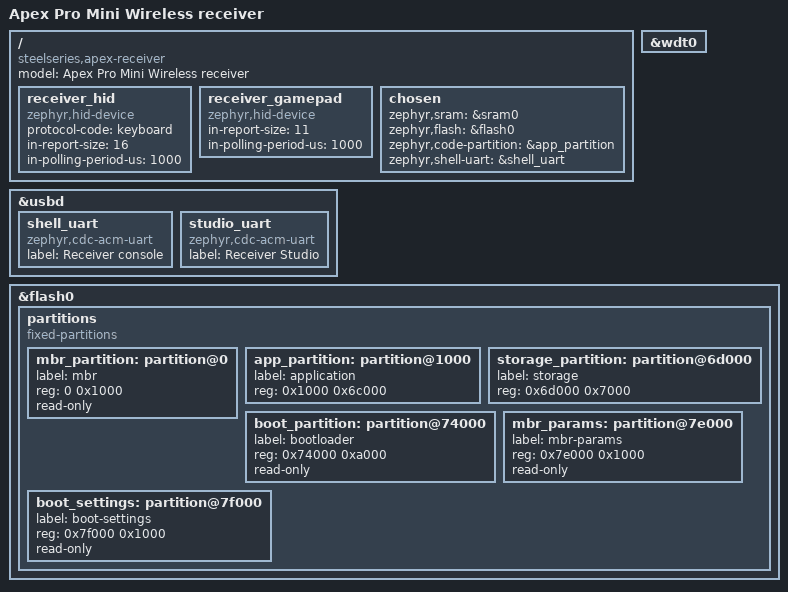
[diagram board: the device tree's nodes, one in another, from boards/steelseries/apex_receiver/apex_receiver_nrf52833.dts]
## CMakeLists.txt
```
cmake_minimum_required(VERSION 3.20.0)
list(APPEND BOARD_ROOT ${CMAKE_CURRENT_SOURCE_DIR})
find_package(Zephyr REQUIRED HINTS $ENV{ZEPHYR_BASE})
project(apex_receiver)
add_subdirectory(../radio ${CMAKE_CURRENT_BINARY_DIR}/apex_radio)
target_sources(app PRIVATE src/main.c src/usb.c src/crypto_test.c ../radio/src/apex_aes_ecb.c)
target_sources(app PRIVATE src/pair_store.c ../radio/src/apex_pair_shell.c)
if(CONFIG_APEX_RECEIVER_RADIO_PROBE)
  target_sources(app PRIVATE ../radio/src/apex_radio_probe.c)
endif()
if(CONFIG_APEX_RECEIVER_RADIO_INPUT)
  target_sources(app PRIVATE src/hid.c src/gamepad.c ../radio/src/apex_input.c ../radio/src/apex_delivery.c)
endif()
if(CONFIG_APEX_RADIO_HOPPING)
  target_sources(app PRIVATE ../radio/src/apex_hop.c ../radio/src/apex_hop_link.c)
endif()
if(CONFIG_APEX_RADIO_SHELL)
  target_sources(app PRIVATE src/keyboard_shell.c src/update.c src/studio_bridge.c ../radio/src/apex_stream.c ../radio/src/apex_shell_link.c)
endif()
target_link_options(zephyr_interface INTERFACE "-Wl,--wrap=tc_aes_encrypt")
if(DEFINED APEX_RECEIVER_BUILD_ID)
  target_compile_definitions(app PRIVATE APEX_RECEIVER_BUILD_ID="${APEX_RECEIVER_BUILD_ID}")
endif()
```

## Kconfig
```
mainmenu "Apex receiver"
source "Kconfig.zephyr"
rsource "../radio/Kconfig"
config APEX_RECEIVER_RADIO_PROBE
    bool "Fixed-channel custom radio hardware test"
    default n
    select ENTROPY_GENERATOR
config APEX_RECEIVER_RADIO_INPUT
    bool "Receive keyboard and consumer reports"
    default n
    select APEX_RECEIVER_RADIO_PROBE
    select USBD_HID_CLASS
config APEX_RECEIVER_RADIO_EVENT_RX
    bool "Wake radio processing on received packets"
    default n
    depends on APEX_RECEIVER_RADIO_PROBE
    select DYNAMIC_INTERRUPTS
```

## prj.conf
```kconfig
CONFIG_USB_DEVICE_STACK_NEXT=y
CONFIG_USBD_CDC_ACM_CLASS=y
CONFIG_SERIAL=y
CONFIG_UART_INTERRUPT_DRIVEN=y
CONFIG_UART_LINE_CTRL=y
CONFIG_CONSOLE=y
CONFIG_UART_CONSOLE=n
CONFIG_SHELL=y
CONFIG_SHELL_BACKEND_SERIAL=y
CONFIG_SHELL_BACKEND_SERIAL_RX_RING_BUFFER_SIZE=512
CONFIG_SHELL_PROMPT_UART="dongle:~$ "
CONFIG_SHELL_STACK_SIZE=2048
CONFIG_LOG=y
CONFIG_LOG_MODE_DEFERRED=y
CONFIG_LOG_DEFAULT_LEVEL=2
CONFIG_LOG_RUNTIME_FILTERING=y
CONFIG_USBD_LOG_LEVEL_WRN=y
CONFIG_UDC_DRIVER_LOG_LEVEL_WRN=y
CONFIG_USBD_CDC_ACM_LOG_LEVEL_ERR=y
CONFIG_WATCHDOG=y
CONFIG_REBOOT=y
CONFIG_HWINFO=y
CONFIG_MAIN_STACK_SIZE=2048
CONFIG_MAIN_THREAD_PRIORITY=1
CONFIG_APEX_RADIO_THREAD_PRIORITY=0
CONFIG_SYSTEM_WORKQUEUE_STACK_SIZE=2048
CONFIG_THREAD_NAME=y
CONFIG_THREAD_STACK_INFO=y
CONFIG_INIT_STACKS=y
CONFIG_ASSERT=y
CONFIG_GPIO=n
CONFIG_PINCTRL=n
CONFIG_BT=n
CONFIG_TINYCRYPT=y
CONFIG_TINYCRYPT_AES=y
CONFIG_TINYCRYPT_AES_CCM=y
CONFIG_TINYCRYPT_SHA256=y
CONFIG_TINYCRYPT_SHA256_HMAC=y
CONFIG_FLASH=y
CONFIG_FLASH_PAGE_LAYOUT=y
CONFIG_FLASH_MAP=y
CONFIG_NVS=y
CONFIG_NVS_DATA_CRC=y
CONFIG_MPU_ALLOW_FLASH_WRITE=y
```

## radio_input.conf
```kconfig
# SPDX-License-Identifier: MIT
CONFIG_APEX_RECEIVER_RADIO_INPUT=y
CONFIG_APEX_RADIO_TEST_CHANNEL=74
CONFIG_APEX_RECEIVER_RADIO_EVENT_RX=y
CONFIG_APEX_RADIO_HOPPING=y
CONFIG_APEX_RADIO_SHELL=y
```

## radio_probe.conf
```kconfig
# SPDX-License-Identifier: MIT
CONFIG_APEX_RECEIVER_RADIO_PROBE=y
```

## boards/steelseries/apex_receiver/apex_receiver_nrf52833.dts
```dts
/* SPDX-License-Identifier: MIT */
/dts-v1/;
#include <nordic/nrf52833_qiaa.dtsi>

/ {
    model = "Apex Pro Mini Wireless receiver";
    compatible = "steelseries,apex-receiver";
    receiver_hid: receiver_hid {
        compatible = "zephyr,hid-device";
        protocol-code = "keyboard";
        in-report-size = <16>;
        in-polling-period-us = <1000>;
    };
    receiver_gamepad: receiver_gamepad {
        compatible = "zephyr,hid-device";
        in-report-size = <11>;
        in-polling-period-us = <1000>;
    };
    chosen {
        zephyr,sram = &sram0;
        zephyr,flash = &flash0;
        zephyr,code-partition = &app_partition;
        zephyr,shell-uart = &shell_uart;
    };
};

zephyr_udc0: &usbd {
    status = "okay";
    shell_uart: shell_uart {
        compatible = "zephyr,cdc-acm-uart";
        label = "Receiver console";
    };
    studio_uart: studio_uart {
        compatible = "zephyr,cdc-acm-uart";
        label = "Receiver Studio";
    };
};

&wdt0 { status = "okay"; };

&flash0 {
    partitions {
        compatible = "fixed-partitions";
        #address-cells = <1>;
        #size-cells = <1>;
        mbr_partition: partition@0 { label = "mbr"; reg = <0 0x1000>; read-only; };
        app_partition: partition@1000 { label = "application"; reg = <0x1000 0x6c000>; };
        storage_partition: partition@6d000 { label = "storage"; reg = <0x6d000 0x7000>; };
        boot_partition: partition@74000 { label = "bootloader"; reg = <0x74000 0xa000>; read-only; };
        mbr_params: partition@7e000 { label = "mbr-params"; reg = <0x7e000 0x1000>; read-only; };
        boot_settings: partition@7f000 { label = "boot-settings"; reg = <0x7f000 0x1000>; read-only; };
    };
};
```

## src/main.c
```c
/* SPDX-License-Identifier: MIT */
#include <zephyr/kernel.h>
#include <zephyr/drivers/watchdog.h>
#include <zephyr/shell/shell.h>
#include <zephyr/sys/reboot.h>
#include <hal/nrf_power.h>
#include "apex_pair.h"
#include "apex_aes.h"
#if IS_ENABLED(CONFIG_APEX_RECEIVER_RADIO_PROBE)
#include "apex_radio_probe.h"
#endif

int receiver_usb_init(void);
#if IS_ENABLED(CONFIG_APEX_RADIO_SHELL)
int receiver_keyboard_command(const struct shell *sh, size_t argc, char **argv);
int receiver_update_start(const struct shell *sh, size_t argc, char **argv);
#endif
#if IS_ENABLED(CONFIG_APEX_RECEIVER_RADIO_INPUT)
#include "apex_radio_input.h"
int receiver_hid_init(void);
int receiver_hid_benchmark(const struct shell *sh, size_t argc, char **argv);
void receiver_hid_poll(void);
void receiver_hid_wait(void);
int receiver_hid_status(const struct shell *sh, size_t argc, char **argv);
int receiver_hid_test_hold(const struct shell *sh, size_t argc, char **argv);
#endif
int receiver_pair_storage_init(const struct shell *sh, size_t argc, char **argv);
int receiver_crypto_test(const struct shell *sh, size_t argc, char **argv);
#ifndef APEX_RECEIVER_BUILD_ID
#define APEX_RECEIVER_BUILD_ID "unrecorded-local-build"
#endif
static uint32_t reset_reason;
static const struct device *const watchdog = DEVICE_DT_GET(DT_NODELABEL(wdt0));
static int watchdog_channel;
static bool inherited_watchdog;

static void enter_bootloader(void)
{
    NRF_POWER->GPREGRET = 0x57;
    sys_reboot(SYS_REBOOT_COLD);
}

void k_sys_fatal_error_handler(unsigned int reason, const struct arch_esf *esf)
{
    ARG_UNUSED(reason);
    ARG_UNUSED(esf);
    enter_bootloader();
    CODE_UNREACHABLE;
}

static int cmd_status(const struct shell *sh, size_t argc, char **argv)
{
    ARG_UNUSED(argc); ARG_UNUSED(argv);
    shell_print(sh, "Apex receiver: radio=%s, HID forwarding=%s",
                IS_ENABLED(CONFIG_APEX_RECEIVER_RADIO_PROBE) ? "enabled" : "disabled",
                IS_ENABLED(CONFIG_APEX_RECEIVER_RADIO_INPUT) ? "enabled" : "disabled");
    shell_print(sh, "build: %s", APEX_RECEIVER_BUILD_ID);
    shell_print(sh, "uptime: %lld ms, reset reason: 0x%08x", k_uptime_get(), reset_reason);
    shell_print(sh, "watchdog: %u ticks, %s", NRF_WDT->CRV,
                inherited_watchdog ? "inherited across reset" : "started by receiver");
    shell_print(sh, "application: 0x1000..0x6d000, pairing storage: 0x6d000..0x74000");
    return 0;
}

static void reboot_work(struct k_work *work)
{
    ARG_UNUSED(work);
    enter_bootloader();
}
static K_WORK_DELAYABLE_DEFINE(dfu_work, reboot_work);

static int cmd_dfu(const struct shell *sh, size_t argc, char **argv)
{
    ARG_UNUSED(argc); ARG_UNUSED(argv);
    shell_print(sh, "Rebooting the dongle into APEXDONGLE.");
    k_work_reschedule(&dfu_work, K_MSEC(200));
    return 0;
}

#if IS_ENABLED(CONFIG_APEX_RECEIVER_RADIO_INPUT)
static int cmd_reconnect(const struct shell *sh, size_t argc, char **argv)
{
    ARG_UNUSED(argc); ARG_UNUSED(argv);
    apex_radio_request_session();
    shell_print(sh, "Radio session restarting.");
    return 0;
}
#endif

SHELL_STATIC_SUBCMD_SET_CREATE(dongle_commands,
#if IS_ENABLED(CONFIG_APEX_RADIO_SHELL)
    SHELL_CMD_ARG(upload, NULL, "Binary keyboard update transfer; used by tools/dongle.py.", receiver_update_start, 1, 0),
#endif
#if IS_ENABLED(CONFIG_APEX_RECEIVER_RADIO_PROBE)
    SHELL_CMD_ARG(radio_test, NULL, "Radio connection and delivery counters.", apex_radio_probe_status, 1, 0),
#endif
#if IS_ENABLED(CONFIG_APEX_RECEIVER_RADIO_INPUT)
    SHELL_CMD_ARG(reconnect, NULL, "Start a fresh radio session without changing pairing.", cmd_reconnect, 1, 0),
    SHELL_CMD_ARG(hid_status, NULL, "USB HID state and media report counters.", receiver_hid_status, 1, 0),
    SHELL_CMD_ARG(hid_bench, NULL, "Pause radio and send 1000 empty USB reports.", receiver_hid_benchmark, 1, 0),
    SHELL_CMD_ARG(hid_test_hold, NULL, "Delay HID for 500 ms and restart the radio session.", receiver_hid_test_hold, 1, 0),
#endif
    SHELL_CMD_ARG(pair_storage_init, NULL, "Initialize unreadable pairing pages; requires confirm.", receiver_pair_storage_init, 1, 1),
    SHELL_CMD_ARG(pair, NULL, "USB pairing: status, write [replace], clear confirm.", apex_pair_shell, 1, 2),
    SHELL_CMD_ARG(status, NULL, "Receiver firmware and reset status.", cmd_status, 1, 0),
    SHELL_CMD_ARG(dfu, NULL, "Enter the dongle USB bootloader.", cmd_dfu, 1, 0),
    SHELL_CMD_ARG(crypto_test, NULL, "Run packet crypto checks locally; no radio traffic.", receiver_crypto_test, 1, 0),
    SHELL_SUBCMD_SET_END);
SHELL_CMD_REGISTER(dongle, &dongle_commands, "Apex receiver commands.", NULL);
#if IS_ENABLED(CONFIG_APEX_RADIO_SHELL)
SHELL_CMD_ARG_REGISTER(keyboard, NULL, "Keyboard commands over radio.", receiver_keyboard_command, 1, 16);
#endif

int main(void)
{
    /* Receiver builds have no Bluetooth controller or other ECB owner. */
    apex_aes_enable();
    reset_reason = NRF_POWER->RESETREAS;
    NRF_POWER->RESETREAS = reset_reason;
    struct wdt_timeout_cfg cfg = {
        .window = {.min = 0, .max = 5000},
        .flags = WDT_FLAG_RESET_SOC,
    };
    /* nRF52 watchdog configuration survives software resets and cannot be
     * changed while running. Adopt it after an update instead of rebooting. */
    inherited_watchdog = NRF_WDT->RUNSTATUS != 0;
    if (!inherited_watchdog) {
        if (!device_is_ready(watchdog)) enter_bootloader();
        watchdog_channel = wdt_install_timeout(watchdog, &cfg);
        if (watchdog_channel < 0 || wdt_setup(watchdog, WDT_OPT_PAUSE_HALTED_BY_DBG)) {
            enter_bootloader();
        }
    }
#if IS_ENABLED(CONFIG_APEX_RECEIVER_RADIO_INPUT)
    if (receiver_hid_init()) enter_bootloader();
#endif
    if (receiver_usb_init()) enter_bootloader();
#if IS_ENABLED(CONFIG_APEX_RECEIVER_RADIO_PROBE)
    apex_radio_probe_start(APEX_RECEIVER);
#endif
    for (;;) {
        if (inherited_watchdog) {
            for (unsigned int i = 0; i < 8; ++i) {
                if (NRF_WDT->RREN & BIT(i)) NRF_WDT->RR[i] = 0x6e524635;
            }
        } else {
            wdt_feed(watchdog, watchdog_channel);
        }
#if IS_ENABLED(CONFIG_APEX_RECEIVER_RADIO_INPUT)
        receiver_hid_poll();
        receiver_hid_wait();
#else
        k_sleep(K_MSEC(100));
#endif
    }
    return 0;
}
```

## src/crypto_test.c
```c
/* SPDX-License-Identifier: MIT */
#include <string.h>
#include <zephyr/kernel.h>
#include <zephyr/shell/shell.h>
#include "apex_packet.h"

/* This local test never accesses pairing storage or the radio. */
int receiver_crypto_test(const struct shell *sh, size_t argc, char **argv)
{
    ARG_UNUSED(argc); ARG_UNUSED(argv);
    static const uint8_t reference[] = {
        0x01, 0x01, 0x00, 0x10, 0x01, 0x00, 0x00, 0x00,
        0xaf, 0x5f, 0xe1, 0xd4, 0x67, 0x03, 0x47, 0xd6,
        0x9c, 0x91, 0x80, 0xba, 0x07, 0xc6, 0x39, 0x55,
        0xe7, 0xb8, 0xd0, 0xf0, 0x68, 0x32, 0x01, 0xb2,
        0xcb, 0x6f, 0x08, 0x20, 0x8f, 0x7b, 0xb3, 0x3c,
    };
    struct apex_session tx, rx;
    uint8_t key[16], kn[16], dn[16], packet[APEX_PACKET_MAX], output[64], type;
    for (unsigned int i = 0; i < 16; ++i) {
        key[i] = i;
        kn[i] = i + 16;
        dn[i] = i + 32;
    }
    int rc = apex_session_init(&tx, key, kn, dn, APEX_KEYBOARD);
    if (!rc) rc = apex_session_init(&rx, key, kn, dn, APEX_RECEIVER);
    uint32_t start = k_cycle_get_32();
    for (unsigned int i = 0; !rc && i < 100; ++i) {
        int n = apex_packet_encode(&tx, APEX_PACKET_INPUT, kn, sizeof(kn), packet, sizeof(packet));
        if (i == 0 && (n != sizeof(reference) || memcmp(packet, reference, sizeof(reference)))) {
            rc = -EIO;
            break;
        }
        if (n < 0 || apex_packet_decode(&rx, packet, n, &type, output, sizeof(output)) != 16 ||
            type != APEX_PACKET_INPUT || memcmp(output, kn, 16)) {
            rc = -EIO;
            break;
        }
        if (apex_packet_decode(&rx, packet, n, &type, output, sizeof(output)) != APEX_PACKET_REPLAY) {
            rc = -EIO;
        }
    }
    uint32_t elapsed = k_cycle_get_32() - start;
    apex_session_clear(&tx);
    apex_session_clear(&rx);
    if (rc) {
        shell_error(sh, "Packet crypto test failed: %d", rc);
    } else {
        shell_print(sh, "100 encrypt/decrypt/replay checks passed; %llu us total",
                    k_cyc_to_us_floor64(elapsed));
    }
    return rc;
}
```

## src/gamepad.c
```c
/* SPDX-License-Identifier: MIT */
#include "gamepad.h"
#include "apex_radio_input.h"
#include <zephyr/kernel.h>
#include <zephyr/usb/class/usbd_hid.h>
#include <zephyr/drivers/usb/udc_buf.h>
#include <zephyr/shell/shell.h>

static const struct device *const hid = DEVICE_DT_GET(DT_NODELABEL(receiver_gamepad));
static const uint8_t descriptor[] = { APEX_GAMEPAD_DESCRIPTOR };
static struct k_spinlock lock;
static uint8_t current[APEX_GAMEPAD_REPORT_SIZE];
static bool ready, busy, dirty, enabled;
static bool live;
static uint32_t received_at;
static uint32_t reports, errors;
UDC_STATIC_BUF_DEFINE(tx, APEX_GAMEPAD_REPORT_SIZE);

void apex_radio_gamepad_receive(bool on, const uint8_t *report)
{
    k_spinlock_key_t key = k_spin_lock(&lock);
    enabled = on;
    live = on;
    received_at = k_uptime_get_32();
    if (on) memcpy(current, report, sizeof(current));
    else apex_gamepad_neutral(current);
    dirty = true;
    k_spin_unlock(&lock, key);
    receiver_usb_gamepad(on);
}

void receiver_gamepad_release(void)
{
    k_spinlock_key_t key = k_spin_lock(&lock);
    live = false;
    apex_gamepad_neutral(current);
    dirty = true;
    k_spin_unlock(&lock, key);
}

static void iface_ready(const struct device *dev, bool on)
{
    ARG_UNUSED(dev);
    k_spinlock_key_t key = k_spin_lock(&lock);
    ready = on;
    dirty = true;
    k_spin_unlock(&lock, key);
}

static void report_done(const struct device *dev, const uint8_t *const report, int status)
{
    ARG_UNUSED(dev); ARG_UNUSED(report);
    k_spinlock_key_t key = k_spin_lock(&lock);
    busy = false;
    if (status) { errors++; dirty = true; }
    else reports++;
    k_spin_unlock(&lock, key);
}

static int get_report(const struct device *dev, uint8_t type, uint8_t id,
                      uint16_t length, uint8_t *const report)
{
    ARG_UNUSED(dev);
    if (type != HID_REPORT_TYPE_INPUT || id || length < sizeof(current)) return -ENOTSUP;
    k_spinlock_key_t key = k_spin_lock(&lock);
    memcpy(report, current, sizeof(current));
    k_spin_unlock(&lock, key);
    return sizeof(current);
}

static const struct hid_device_ops ops = {
    .iface_ready = iface_ready,
    .get_report = get_report,
    .input_report_complete = report_done,
};

void receiver_gamepad_poll(void)
{
    k_spinlock_key_t key = k_spin_lock(&lock);
    if (live && k_uptime_get_32() - received_at >= 100) {
        apex_gamepad_neutral(current);
        dirty = true;
        live = false;
    }
    if (!ready || busy || !dirty) { k_spin_unlock(&lock, key); return; }
    memcpy(tx, current, sizeof(current));
    busy = true;
    dirty = false;
    k_spin_unlock(&lock, key);
    int rc = hid_device_submit_report(hid, sizeof(current), tx);
    if (rc) {
        key = k_spin_lock(&lock);
        busy = false;
        dirty = true;
        errors++;
        k_spin_unlock(&lock, key);
    }
}

int receiver_gamepad_init(void)
{
    apex_gamepad_neutral(current);
    return hid_device_register(hid, descriptor, sizeof(descriptor), &ops);
}

void receiver_gamepad_status(const struct shell *sh)
{
    k_spinlock_key_t key = k_spin_lock(&lock);
    bool e = enabled, r = ready, b = busy;
    uint32_t n = reports, err = errors;
    k_spin_unlock(&lock, key);
    shell_print(sh, "GAMEPAD enabled=%u ready=%u busy=%u reports=%u errors=%u", e, r, b, n, err);
}
```

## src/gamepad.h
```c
/* SPDX-License-Identifier: MIT */
#ifndef RECEIVER_GAMEPAD_H
#define RECEIVER_GAMEPAD_H
#include <stdbool.h>
struct shell;
int receiver_gamepad_init(void);
void receiver_gamepad_poll(void);
void receiver_gamepad_release(void);
void receiver_gamepad_status(const struct shell *sh);
void receiver_usb_gamepad(bool enabled);
#endif
```

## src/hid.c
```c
/* SPDX-License-Identifier: MIT */
#include "apex_radio_input.h"
#include "apex_latency.h"
#include "gamepad.h"
#include <string.h>
#include <zephyr/kernel.h>
#include <zephyr/usb/class/usbd_hid.h>
#include <zephyr/drivers/usb/udc_buf.h>
#include <zephyr/sys/atomic.h>
#include <zephyr/shell/shell.h>
#include <zephyr/sys/byteorder.h>

/* Report bodies match v0.1.4: six keyboard usages and six 16-bit consumer usages. */
static const uint8_t descriptor[] = {
    0x05,0x01, 0x09,0x06, 0xa1,0x01, 0x85,0x01,
    0x05,0x07, 0x19,0xe0, 0x29,0xe7, 0x15,0x00, 0x25,0x01,
    0x75,0x01, 0x95,0x08, 0x81,0x02,
    0x75,0x08, 0x95,0x01, 0x81,0x03,
    0x05,0x08, 0x19,0x01, 0x29,0x05, 0x75,0x01, 0x95,0x05, 0x91,0x02,
    0x75,0x03, 0x95,0x01, 0x91,0x03,
    0x05,0x07, 0x19,0x00, 0x29,0xff, 0x15,0x00, 0x26,0xff,0x00,
    0x75,0x08, 0x95,0x06, 0x81,0x00, 0xc0,
    0x05,0x0c, 0x09,0x01, 0xa1,0x01, 0x85,0x02,
    0x15,0x00, 0x26,0xff,0x0f, 0x19,0x00, 0x2a,0xff,0x0f,
    0x75,0x10, 0x95,0x06, 0x81,0x00, 0xc0,
};
static const struct device *const hid = DEVICE_DT_GET(DT_NODELABEL(receiver_hid));
UDC_STATIC_BUF_DEFINE(report, 16);
static struct k_spinlock lock;
static bool ready, busy;
static uint8_t release_mask = 3, protocol = HID_PROTOCOL_REPORT;
static uint32_t generation, pending_generation, pending_sequence, delivered_sequence;
static uint8_t pending_type;
static uint8_t keyboard[8], consumer[12];
static atomic_t leds;
static int64_t hold_until;
static uint32_t completed[2], releases, submit_errors, transfer_errors;
static uint16_t last_media_usage;
static uint32_t submitted_at, delivered_at, usb_max_us;
static struct apex_latency usb_latency;
static struct apex_latency usb_interval;
static uint32_t last_usb_at, last_usb_generation;
static bool have_usb_completion;
static struct apex_delivery_rx delivery;
static K_SEM_DEFINE(hid_event, 0, 1);

void receiver_hid_wait(void)
{
    /* Retry temporary submission failures even if USB produces no callback. */
    k_sem_take(&hid_event, K_MSEC(1));
}

void apex_radio_delivery_status(struct apex_delivery_ack *ack)
{
    k_spinlock_key_t key = k_spin_lock(&lock);
    apex_delivery_status(&delivery, atomic_get(&leds), ack);
    k_spin_unlock(&lock, key);
}

uint32_t apex_radio_completed(uint32_t *completed_at)
{
    k_spinlock_key_t key = k_spin_lock(&lock);
    uint32_t sequence = release_mask ? 0 : delivered_sequence;
    *completed_at = delivered_at;
    k_spin_unlock(&lock, key);
    return sequence;
}

void apex_radio_release(void)
{
    k_spinlock_key_t key = k_spin_lock(&lock);
    generation++;
    releases++;
    delivered_sequence = 0;
    apex_delivery_rx_reset(&delivery);
    release_mask = 3;
    memset(keyboard, 0, sizeof(keyboard));
    memset(consumer, 0, sizeof(consumer));
    k_spin_unlock(&lock, key);
    receiver_gamepad_release();
    k_sem_give(&hid_event);
}

static void iface_ready(const struct device *dev, bool is_ready)
{
    ARG_UNUSED(dev);
    k_spinlock_key_t key = k_spin_lock(&lock);
    ready = is_ready;
    k_spin_unlock(&lock, key);
    apex_radio_release();
    apex_radio_request_session();
}

static void report_done(const struct device *dev, const uint8_t *data, int status)
{
    ARG_UNUSED(dev); ARG_UNUSED(data);
    bool notify = false;
    k_spinlock_key_t key = k_spin_lock(&lock);
    if (status) transfer_errors++;
    if (!status && busy && pending_generation == generation) {
        delivered_sequence = pending_sequence;
        if (pending_sequence) {
            apex_delivery_complete(&delivery, pending_sequence);
            delivered_at = k_cycle_get_32();
            if (have_usb_completion && last_usb_generation == pending_generation)
                apex_latency_add(&usb_interval, k_cyc_to_us_floor32(delivered_at - last_usb_at));
            last_usb_at = delivered_at;
            last_usb_generation = pending_generation;
            have_usb_completion = true;
            uint32_t elapsed = k_cyc_to_us_floor32(delivered_at - submitted_at);
            apex_latency_add(&usb_latency, elapsed);
            if (elapsed > usb_max_us) usb_max_us = elapsed;
            notify = true;
            completed[pending_type - 1]++;
            if (pending_type == APEX_INPUT_CONSUMER && sys_get_le16(consumer)) {
                last_media_usage = sys_get_le16(consumer);
            }
        }
        if (!pending_sequence) release_mask &= ~(1u << (pending_type - 1));
    }
    busy = false;
    k_spin_unlock(&lock, key);
    k_sem_give(&hid_event);
    if (notify) apex_radio_delivery_notify();
}

static void set_protocol(const struct device *dev, uint8_t value)
{
    ARG_UNUSED(dev);
    k_spinlock_key_t key = k_spin_lock(&lock);
    protocol = value;
    k_spin_unlock(&lock, key);
    apex_radio_release();
    apex_radio_request_session();
}

static int get_report(const struct device *dev, uint8_t type, uint8_t id,
                      uint16_t length, uint8_t *buf)
{
    ARG_UNUSED(dev);
    k_spinlock_key_t key = k_spin_lock(&lock);
    bool boot = protocol == HID_PROTOCOL_BOOT;
    if (boot && id == 0) id = APEX_INPUT_KEYBOARD;
    if (type != HID_REPORT_TYPE_INPUT || !apex_input_size(id)) {
        k_spin_unlock(&lock, key);
        return -ENOTSUP;
    }
    size_t n = apex_input_size(id), prefix = boot ? 0 : 1;
    if (length < n + prefix || (boot && id != APEX_INPUT_KEYBOARD)) {
        k_spin_unlock(&lock, key);
        return -EINVAL;
    }
    if (prefix) buf[0] = id;
    memcpy(buf + prefix, id == APEX_INPUT_KEYBOARD ? keyboard : consumer, n);
    k_spin_unlock(&lock, key);
    return n + prefix;
}

static int set_report(const struct device *dev, uint8_t type, uint8_t id,
                      uint16_t length, const uint8_t *buf)
{
    ARG_UNUSED(dev);
    if (type != HID_REPORT_TYPE_OUTPUT || (id != 1 && id != 0) || length != 1) return -EINVAL;
    atomic_set(&leds, buf[0] & 0x1f);
    return 0;
}

static const struct hid_device_ops ops = {
    .iface_ready = iface_ready, .input_report_complete = report_done,
    .get_report = get_report, .set_report = set_report, .set_protocol = set_protocol,
};

static int submit(uint32_t sequence, uint8_t type, const uint8_t *data, uint32_t expected_generation)
{
    k_spinlock_key_t key = k_spin_lock(&lock);
    if (expected_generation != generation) {
        k_spin_unlock(&lock, key);
        return -ECANCELED;
    }
    if (k_uptime_get() < hold_until) {
        k_spin_unlock(&lock, key);
        return -EAGAIN;
    }
    if (sequence && sequence == delivered_sequence && !release_mask) {
        k_spin_unlock(&lock, key);
        return 0;
    }
    if (!ready || busy || (sequence && release_mask)) {
        k_spin_unlock(&lock, key);
        return -EAGAIN;
    }
    if (protocol == HID_PROTOCOL_BOOT && type == APEX_INPUT_CONSUMER) {
        if (!sequence) release_mask &= ~2u;
        else {
            delivered_sequence = sequence;
            delivered_at = k_cycle_get_32();
            apex_delivery_complete(&delivery, sequence);
        }
        k_spin_unlock(&lock, key);
        k_sem_give(&hid_event);
        apex_radio_delivery_notify();
        return 0;
    }
    size_t n = apex_input_size(type), prefix = protocol == HID_PROTOCOL_BOOT ? 0 : 1;
    if (prefix) report[0] = type;
    memcpy(report + prefix, data, n);
    memcpy(type == APEX_INPUT_KEYBOARD ? keyboard : consumer, data, n);
    pending_sequence = sequence;
    pending_type = type;
    pending_generation = generation;
    submitted_at = k_cycle_get_32();
    busy = true;
    k_spin_unlock(&lock, key);
    int rc = hid_device_submit_report(hid, n + prefix, report);
    if (rc) {
        key = k_spin_lock(&lock);
        submit_errors++;
        busy = false;
        k_spin_unlock(&lock, key);
    }
    return rc ? rc : -EAGAIN;
}

int apex_radio_deliver(const struct apex_input_frame *frame)
{
    k_spinlock_key_t key = k_spin_lock(&lock);
    int rc = apex_delivery_receive(&delivery, frame);
    k_spin_unlock(&lock, key);
    if (!rc) k_sem_give(&hid_event);
    return rc == -2 ? -EAGAIN : rc < 0 ? -EINVAL : 0;
}

void receiver_hid_poll(void)
{
    static const uint8_t zero[12];
    k_spinlock_key_t key = k_spin_lock(&lock);
    uint8_t type = release_mask & 1 ? APEX_INPUT_KEYBOARD :
                   release_mask & 2 ? APEX_INPUT_CONSUMER : 0;
    uint32_t current_generation = generation;
    struct apex_input_frame frame;
    bool queued = !type && apex_delivery_front(&delivery, &frame);
    k_spin_unlock(&lock, key);
    if (type) (void)submit(0, type, zero, current_generation);
    else if (queued) (void)submit(frame.sequence, frame.type, frame.data, current_generation);
    receiver_gamepad_poll();
}

int receiver_hid_init(void)
{
    int rc = hid_device_register(hid, descriptor, sizeof(descriptor), &ops);
    return rc ? rc : receiver_gamepad_init();
}

int receiver_hid_benchmark(const struct shell *sh, size_t argc, char **argv)
{
    ARG_UNUSED(argc); ARG_UNUSED(argv);
    if (!apex_radio_pause()) return -EBUSY;
    apex_radio_release();
    int rc = 0;
    int64_t deadline = k_uptime_get() + 1000;
    for (;;) {
        k_spinlock_key_t key = k_spin_lock(&lock);
        bool available = ready && !busy && !release_mask;
        k_spin_unlock(&lock, key);
        if (available) break;
        if (k_uptime_get() >= deadline) { rc = -ETIMEDOUT; goto done; }
        k_sleep(K_MSEC(1));
    }
    uint32_t sent = 0, complete = 0, started = k_cycle_get_32();
    deadline = k_uptime_get() + 5000;
    while (complete < 1000 && k_uptime_get() < deadline) {
        while (sent < 1000) {
            struct apex_input_frame frame = {.sequence = sent + 1, .type = APEX_INPUT_KEYBOARD};
            int result = apex_radio_deliver(&frame);
            if (result == -EAGAIN) break;
            if (result) { rc = result; goto report; }
            sent++;
        }
        uint32_t completed_at;
        complete = apex_radio_completed(&completed_at);
        if (complete < 1000) k_sleep(K_MSEC(1));
    }
    if (complete < 1000) rc = -ETIMEDOUT;
report:;
    uint32_t elapsed = k_cyc_to_us_floor32(k_cycle_get_32() - started);
    shell_print(sh, "USB_BENCH sent=%u completed=%u elapsed_us=%u reports_per_s=%llu error=%d",
                sent, complete, elapsed, elapsed ? (unsigned long long)complete * 1000000 / elapsed : 0, rc);
done:
    apex_radio_release();
    apex_radio_resume();
    return rc;
}

int receiver_hid_status(const struct shell *sh, size_t argc, char **argv)
{
    receiver_gamepad_status(sh);
    ARG_UNUSED(argc); ARG_UNUSED(argv);
    k_spinlock_key_t key = k_spin_lock(&lock);
    bool r = ready, b = busy;
    uint8_t p = protocol, mask = release_mask;
    uint32_t keys = completed[0], media = completed[1], cleared = releases, errors = submit_errors;
    uint32_t failed = transfer_errors;
    uint32_t usb_us = usb_max_us;
    struct apex_latency latency = usb_latency;
    struct apex_latency interval = usb_interval;
    uint16_t usage = last_media_usage;
    k_spin_unlock(&lock, key);
    shell_print(sh, "HID ready=%u busy=%u protocol=%u release_pending=%u leds=%02lx",
                r, b, p, mask, (unsigned long)atomic_get(&leds));
    shell_print(sh, "HID keyboard=%lu consumer=%lu releases=%lu submit_errors=%lu last_media=%04x",
                (unsigned long)keys, (unsigned long)media, (unsigned long)cleared,
                (unsigned long)errors, usage);
    shell_print(sh, "HID transfer_errors=%lu", (unsigned long)failed);
    shell_print(sh, "HID submit_to_complete_max_us=%lu", (unsigned long)usb_us);
    shell_print(sh, "USB_COMPLETE count=%u min_us=%u max_us=%u total_us=%llu",
                latency.count, latency.min_us, latency.max_us,
                (unsigned long long)latency.total_us);
    shell_print(sh, "USB_COMPLETE buckets=%u,%u,%u,%u,%u,%u",
                latency.buckets[0], latency.buckets[1], latency.buckets[2],
                latency.buckets[3], latency.buckets[4], latency.buckets[5]);
    shell_print(sh, "USB_INTERVAL count=%u min_us=%u max_us=%u total_us=%llu",
                interval.count, interval.min_us, interval.max_us,
                (unsigned long long)interval.total_us);
    shell_print(sh, "USB_INTERVAL buckets=%u,%u,%u,%u,%u,%u",
                interval.buckets[0], interval.buckets[1], interval.buckets[2],
                interval.buckets[3], interval.buckets[4], interval.buckets[5]);
    return 0;
}

int receiver_hid_test_hold(const struct shell *sh, size_t argc, char **argv)
{
    ARG_UNUSED(argc); ARG_UNUSED(argv);
    /* A bounded USB stall for testing radio liveness independently of delivery. */
    k_spinlock_key_t key = k_spin_lock(&lock);
    hold_until = k_uptime_get() + 500;
    k_spin_unlock(&lock, key);
    apex_radio_release();
    apex_radio_request_session();
    shell_print(sh, "Holding HID submissions for 500 ms; requesting a fresh radio session.");
    return 0;
}
```

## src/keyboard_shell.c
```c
/* SPDX-License-Identifier: MIT */
#include "apex_shell_link.h"
#include "apex_radio_input.h"
#include <zephyr/kernel.h>
#include <zephyr/shell/shell.h>
#include <zephyr/sys/byteorder.h>
#include <string.h>

int receiver_keyboard_command(const struct shell *sh, size_t argc, char **argv)
{
    if (argc == 1) {
        shell_print(sh, "Usage: keyboard <command> [arguments]");
        shell_print(sh, "  battery        Battery and charging status");
        shell_print(sh, "  radio          Connection and delivery counters");
        shell_print(sh, "  gamepad        Analog controller status (on/off to change)");
        shell_print(sh, "  info           Keyboard status summary");
        shell_print(sh, "Other commands use the same names as the keyboard's apex shell.");
        return 0;
    }
    char command[APEX_SHELL_COMMAND_MAX] = "apex";
    size_t used = strlen(command);
    for (size_t i = 1; i < argc; i++) {
        const char *arg = i == 1 && !strcmp(argv[i], "radio") ? "radio_test" : argv[i];
        size_t n = strlen(arg);
        if (used + n + 1 >= sizeof(command)) {
            shell_error(sh, "Keyboard command is too long.");
            return -E2BIG;
        }
        command[used++] = ' ';
        memcpy(command + used, arg, n);
        used += n;
    }
    command[used] = '\0';
    if (!apex_radio_input_connected()) {
        shell_error(sh, "Keyboard is not connected. Wake it or select dongle mode.");
        return -ENOTCONN;
    }
    uint32_t generation = apex_shell_generation();
    int64_t deadline = k_uptime_get() + APEX_SHELL_TIMEOUT_MS;
    int rc = 0;
    for (size_t offset = 0; offset < used;) {
        uint8_t frame[APEX_STREAM_DATA_MAX];
        size_t n = MIN(used - offset, sizeof(frame) - 1);
        frame[0] = offset + n == used ? APEX_SHELL_COMMAND_END : APEX_SHELL_COMMAND;
        memcpy(frame + 1, command + offset, n);
        rc = apex_shell_send(generation, frame, n + 1, deadline);
        if (rc) goto failed;
        offset += n;
    }
    shell_print(sh, "[keyboard]");
    while (k_uptime_get() < deadline) {
        uint8_t frame[APEX_STREAM_DATA_MAX];
        int n = apex_shell_read(generation, frame);
        if (n < 0) { rc = n; goto failed; }
        if (!n) { k_sleep(K_MSEC(1)); continue; }
        if (frame[0] == APEX_SHELL_OUTPUT) {
            shell_fprintf(sh, SHELL_NORMAL, "%.*s", n - 1, (const char *)frame + 1);
        } else if (frame[0] == APEX_SHELL_RESULT && n == 5) {
            rc = (int32_t)sys_get_le32(frame + 1);
            shell_print(sh, "\n[keyboard result: %d]", rc);
            return rc;
        } else { rc = -EPROTO; goto failed; }
    }
    rc = -ETIMEDOUT;
failed:
    apex_radio_request_session();
    shell_error(sh, "Keyboard reply incomplete (%d). The command may have run; it was not retried.", rc);
    return rc;
}
```

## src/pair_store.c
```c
/* SPDX-License-Identifier: MIT */
#include "apex_pair.h"
#include <zephyr/kernel.h>
#include <zephyr/drivers/flash.h>
#include <zephyr/fs/nvs.h>
#include <zephyr/storage/flash_map.h>
#include <zephyr/shell/shell.h>
#include <string.h>

static struct nvs_fs bonds;
static K_MUTEX_DEFINE(store_mutex);
static bool mounted;

static int mount_store(void)
{
    if (mounted) return 0;
    struct flash_pages_info page;
    bonds.flash_device = FIXED_PARTITION_DEVICE(storage_partition);
    bonds.offset = FIXED_PARTITION_OFFSET(storage_partition);
    if (!device_is_ready(bonds.flash_device)) return -ENODEV;
    int rc = flash_get_page_info_by_offs(bonds.flash_device, bonds.offset, &page);
    if (rc) return rc;
    bonds.sector_size = page.size;
    bonds.sector_count = FIXED_PARTITION_SIZE(storage_partition) / page.size;
    rc = nvs_mount(&bonds);
    if (!rc) mounted = true;
    return rc;
}

int receiver_pair_storage_init(const struct shell *sh, size_t argc, char **argv)
{
    if (argc != 2 || strcmp(argv[1], "confirm")) {
        shell_error(sh, "Use pair_storage_init confirm to erase only the reserved pairing pages.");
        return -EINVAL;
    }
    k_mutex_lock(&store_mutex, K_FOREVER);
    int rc = mount_store();
    /* Never erase a readable store or treat a hardware failure as corruption. */
    if (rc == -EDEADLK) {
        rc = flash_erase(FIXED_PARTITION_DEVICE(storage_partition),
                         FIXED_PARTITION_OFFSET(storage_partition),
                         FIXED_PARTITION_SIZE(storage_partition));
        if (!rc) rc = mount_store();
    }
    k_mutex_unlock(&store_mutex);
    if (rc) shell_error(sh, "Pairing storage initialization failed: %d", rc);
    else shell_print(sh, "Pairing storage ready.");
    return rc;
}

int apex_bond_load(uint8_t record[APEX_BOND_SIZE])
{
    k_mutex_lock(&store_mutex, K_FOREVER);
    int rc = mount_store();
    if (!rc) {
        rc = nvs_read(&bonds, 1, record, APEX_BOND_SIZE);
        if (rc >= 0) rc = rc == APEX_BOND_SIZE && apex_bond_valid(record) ? 0 : -EBADMSG;
    }
    k_mutex_unlock(&store_mutex);
    return rc;
}

int apex_bond_store(const uint8_t record[APEX_BOND_SIZE])
{
    if (!apex_bond_valid(record)) return -EINVAL;
    k_mutex_lock(&store_mutex, K_FOREVER);
    int rc = mount_store();
    if (!rc) {
        rc = nvs_write(&bonds, 1, record, APEX_BOND_SIZE);
        if (rc >= 0) rc = 0;
    }
    k_mutex_unlock(&store_mutex);
    return rc;
}

int apex_bond_delete(void)
{
    k_mutex_lock(&store_mutex, K_FOREVER);
    int rc = mount_store();
    if (!rc) rc = nvs_delete(&bonds, 1);
    if (rc == -ENOENT) rc = 0;
    k_mutex_unlock(&store_mutex);
    return rc;
}
```

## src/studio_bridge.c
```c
/* SPDX-License-Identifier: MIT */
/* Transparent ZMK Studio bridge on the receiver.
 *
 * A dedicated USB CDC ("Receiver Studio") that the host's ZMK Studio connects to,
 * pumped byte-for-byte over the 2.4 GHz link so the keyboard can be configured
 * while wireless. Host bytes become APEX_STUDIO_DATA frames; the keyboard's
 * APEX_STUDIO_REPLY frames are written back to the host. The bytes are opaque -
 * ZMK Studio applies its own SOF/EOF framing, so this bridge understands none of
 * it.
 *
 * The CDC endpoints are serviced through the interrupt-driven UART API (the poll
 * API does not drain the cdc-acm OUT endpoint on the device_next USB stack, so a
 * host write would stall on flow control). The ISR only moves bytes to/from two
 * single-producer/single-consumer rings; the thread does the radio I/O, which can
 * block and must never run in interrupt context.
 *
 * The radio carries a single shared stream (also used by the `keyboard` shell
 * command and firmware `update`). To avoid stealing their frames, the bridge only
 * reads the radio while a Studio session is live - within SESSION_IDLE_MS of the
 * last Studio byte in either direction. Studio and those maintenance paths are
 * therefore mutually exclusive, which is fine: nobody flashes firmware while
 * editing a keymap.
 */
#include "apex_shell_link.h"
#include "apex_radio_input.h"
#include <zephyr/kernel.h>
#include <zephyr/device.h>
#include <zephyr/drivers/uart.h>
#include <zephyr/sys/ring_buffer.h>
#include <zephyr/sys/util.h>

#define STUDIO_UART DEVICE_DT_GET(DT_NODELABEL(studio_uart))
#define SESSION_IDLE_MS 3000

RING_BUF_DECLARE(studio_usb_rx, 512); /* host -> radio */
RING_BUF_DECLARE(studio_usb_tx, 512); /* radio -> host */

static const struct device *studio_dev;

static void studio_isr(const struct device *dev, void *user_data)
{
    ARG_UNUSED(user_data);
    if (!uart_irq_update(dev)) {
        return;
    }
    /* host -> device: pull the OUT endpoint into the RX ring for the thread. */
    while (uart_irq_rx_ready(dev)) {
        uint8_t *buf;
        uint32_t space = ring_buf_put_claim(&studio_usb_rx, &buf, 64);
        if (!space) {
            uint8_t drop[32];
            (void)uart_fifo_read(dev, drop, sizeof(drop)); /* ring full: shed a little */
            continue;
        }
        int got = uart_fifo_read(dev, buf, space);
        ring_buf_put_finish(&studio_usb_rx, MAX(got, 0));
        if (got <= 0) {
            break;
        }
    }
    /* device -> host: drain the TX ring into the IN endpoint. */
    if (uart_irq_tx_ready(dev)) {
        while (ring_buf_size_get(&studio_usb_tx) > 0) {
            uint8_t *buf;
            uint32_t avail = ring_buf_get_claim(&studio_usb_tx, &buf, 64);
            if (!avail) {
                break;
            }
            int sent = uart_fifo_fill(dev, buf, avail);
            ring_buf_get_finish(&studio_usb_tx, MAX(sent, 0));
            if (sent <= 0) {
                break;
            }
        }
        if (ring_buf_size_get(&studio_usb_tx) == 0) {
            uart_irq_tx_disable(dev);
        }
    }
}

static void studio_bridge_main(void)
{
    int64_t last_activity = 0;

    studio_dev = STUDIO_UART;
    while (!device_is_ready(studio_dev)) {
        k_sleep(K_MSEC(100));
    }
    uart_irq_callback_user_data_set(studio_dev, studio_isr, NULL);
    uart_irq_rx_enable(studio_dev);

    for (;;) {
        bool worked = false;
        int64_t now = k_uptime_get();

        /* host -> keyboard: forward buffered Studio bytes in <=46-byte frames. */
        if (apex_radio_input_connected() && ring_buf_size_get(&studio_usb_rx) > 0) {
            uint8_t frame[APEX_STREAM_DATA_MAX];
            frame[0] = APEX_STUDIO_DATA;
            uint32_t n = ring_buf_get(&studio_usb_rx, frame + 1, sizeof(frame) - 1);
            if (n) {
                apex_shell_bulk_touch();
                (void)apex_shell_send(apex_shell_generation(), frame, n + 1, now + 2000);
                last_activity = now;
                worked = true;
            }
        }

        /* keyboard -> host: only while a session is live, so idle periods leave the
         * shared stream to the shell/update paths. */
        if (now - last_activity < SESSION_IDLE_MS) {
            uint8_t frame[APEX_STREAM_DATA_MAX];
            int n = apex_shell_read(apex_shell_generation(), frame);
            if (n > 1 && frame[0] == APEX_STUDIO_REPLY) {
                ring_buf_put(&studio_usb_tx, frame + 1, n - 1);
                uart_irq_tx_enable(studio_dev);
                last_activity = now;
                worked = true;
            }
        }

        if (!worked) {
            k_sleep(K_MSEC(1));
        }
    }
}

K_THREAD_DEFINE(studio_bridge, 1536, studio_bridge_main, NULL, NULL, NULL, 7, 0, 0);
```

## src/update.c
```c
/* SPDX-License-Identifier: MIT */
#include "apex_shell_link.h"
#include "apex_radio_input.h"
#include <zephyr/kernel.h>
#include <zephyr/shell/shell.h>
#include <zephyr/sys/byteorder.h>
#include <zephyr/sys/crc.h>
#include <string.h>

/* USB frame: AUP1, offset:u32, length:u16, reserved:u16, data, CRC32.
 * A zero-length frame closes the transfer. Host waits for each block's reply. */
static uint8_t block[272];
static size_t used;
static uint32_t generation;
static int64_t last_input;

static void reply(const struct shell *sh, int rc, uint32_t received)
{
    uint8_t response[16] = { 'A', 'U', 'R', '1' };
    sys_put_le32(received, response + 4);
    sys_put_le32((uint32_t)rc, response + 8);
    sys_put_le32(crc32_ieee(response, 12), response + 12);
    size_t sent = 0;
    int64_t end = k_uptime_get() + 2000;
    while (sent < sizeof(response) && k_uptime_get() < end) {
        size_t n = 0;
        if (sh->iface->api->write(sh->iface, response + sent, sizeof(response) - sent, &n)) break;
        sent += n;
        if (!n) k_sleep(K_MSEC(1));
    }
}

static int forward(uint32_t offset, const uint8_t *data, size_t length, uint32_t *received)
{
    for (size_t sent = 0; sent < length;) {
        size_t n = MIN(length - sent, 32);
        uint8_t frame[37] = { APEX_UPDATE_DATA };
        sys_put_le32(offset + sent, frame + 1);
        memcpy(frame + 5, data + sent, n);
        int64_t end = k_uptime_get() + 2000;
        int rc = apex_shell_send(generation, frame, n + 5, end);
        if (rc) return rc;
        for (;;) {
            uint8_t response[APEX_STREAM_DATA_MAX];
            int count = apex_shell_read(generation, response);
            if (count < 0) return count;
            if (count) {
                if (count != 9 || response[0] != APEX_UPDATE_REPLY) return -EPROTO;
                *received = sys_get_le32(response + 5);
                rc = (int32_t)sys_get_le32(response + 1);
                if (rc) return rc;
                if (*received != offset + sent + n) return -EPROTO;
                break;
            }
            if (k_uptime_get() >= end) return -ETIMEDOUT;
            k_sleep(K_MSEC(1));
        }
        sent += n;
    }
    return 0;
}

static void receive(const struct shell *sh, uint8_t *data, size_t length)
{
    /* An abandoned partial USB block can be cancelled with Ctrl+C after 2 s.
     * No incomplete block is forwarded to the keyboard. */
    if (k_uptime_get() - last_input > 2000) used = 0;
    last_input = k_uptime_get();
    for (size_t i = 0; i < length; i++) {
        if (!used && data[i] == 3) { shell_set_bypass(sh, NULL); return; }
        block[used++] = data[i];
        if (used < 12) continue;
        uint32_t offset = sys_get_le32(block + 4);
        uint16_t n = sys_get_le16(block + 8);
        if (memcmp(block, "AUP1", 4) || n > 256 || sys_get_le16(block + 10) ||
            n > 4096 - offset % 4096) {
            reply(sh, -EINVAL, 0);
            used = 0;
            shell_set_bypass(sh, NULL);
            return;
        }
        if (used < (size_t)n + 16) continue;
        int rc = crc32_ieee(block, n + 12) == sys_get_le32(block + n + 12) ? 0 : -EBADMSG;
        uint32_t received = offset;
        if (!rc && n) rc = forward(offset, block + 12, n, &received);
        reply(sh, rc, received);
        used = 0;
        last_input = k_uptime_get();
        if (rc || !n) {
            shell_set_bypass(sh, NULL);
            if (rc) apex_radio_request_session();
            return;
        }
    }
}

int receiver_update_start(const struct shell *sh, size_t argc, char **argv)
{
    ARG_UNUSED(argc); ARG_UNUSED(argv);
    if (!apex_radio_input_connected()) return -ENOTCONN;
    generation = apex_shell_generation();
    used = 0;
    last_input = k_uptime_get();
    shell_set_bypass(sh, receive);
    shell_print(sh, "APX-UPLOAD-1 READY");
    return 0;
}
```

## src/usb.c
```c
/* SPDX-License-Identifier: MIT */
#include <zephyr/device.h>
#include <zephyr/usb/usbd.h>
#include <zephyr/kernel.h>
#include <zephyr/logging/log.h>
#include "gamepad.h"
LOG_MODULE_REGISTER(receiver_usb, LOG_LEVEL_WRN);

/* Local development IDs, matching the existing receiver allocation. */
USBD_DEVICE_DEFINE(receiver_usb, DEVICE_DT_GET(DT_NODELABEL(zephyr_udc0)), 0x1d50, 0x6171);
USBD_DESC_LANG_DEFINE(receiver_lang);
USBD_DESC_MANUFACTURER_DEFINE(receiver_mfr, "Apex community firmware");
USBD_DESC_PRODUCT_DEFINE(receiver_product, "Apex wireless receiver");
USBD_DESC_SERIAL_NUMBER_DEFINE(receiver_serial);
USBD_DESC_CONFIG_DEFINE(receiver_cfg_desc, "Receiver");
USBD_CONFIGURATION_DEFINE(receiver_cfg, 0, 50, &receiver_cfg_desc);

static atomic_t gamepad_target, started;
static bool gamepad_present;

static int register_classes(bool gamepad)
{
    const char *blocklist[] = { "hid_1", NULL };
    return usbd_register_all_classes(&receiver_usb, USBD_SPEED_FS, 1,
                                     gamepad ? NULL : blocklist);
}

static int bring_up(bool gamepad)
{
    /* usbd_shutdown removes classes and string descriptors, but retains the
     * configuration node. Re-add its strings before registering classes. */
    struct usbd_desc_node *descriptors[] = {
        &receiver_lang, &receiver_mfr, &receiver_product, &receiver_serial,
    };
    int rc;
    for (size_t i = 0; i < ARRAY_SIZE(descriptors); ++i) {
        rc = usbd_add_descriptor(&receiver_usb, descriptors[i]);
        if (rc) return rc;
    }
    rc = usbd_add_configuration(&receiver_usb, USBD_SPEED_FS, &receiver_cfg);
    if (!rc) rc = register_classes(gamepad);
    if (!rc) rc = usbd_init(&receiver_usb);
    if (!rc) rc = usbd_enable(&receiver_usb);
    return rc;
}

static void reconfigure(struct k_work *work)
{
    ARG_UNUSED(work);
    if (!atomic_get(&started)) return;
    bool requested = atomic_get(&gamepad_target) != 0;
    if (requested == gamepad_present) return;
    (void)usbd_disable(&receiver_usb);
    (void)usbd_shutdown(&receiver_usb);
    int rc = bring_up(requested);
    if (!rc) {
        gamepad_present = requested;
    } else {
        LOG_ERR("Cannot change gamepad interface: %d", rc);
        (void)usbd_disable(&receiver_usb);
        (void)usbd_shutdown(&receiver_usb);
        if (bring_up(gamepad_present)) LOG_ERR("Cannot restore USB interfaces");
    }
    if (requested != (atomic_get(&gamepad_target) != 0)) k_work_submit(work);
}
static K_WORK_DEFINE(class_work, reconfigure);

void receiver_usb_gamepad(bool enabled)
{
    if (atomic_set(&gamepad_target, enabled) != enabled) k_work_submit(&class_work);
}

static void usb_event(struct usbd_context *ctx, const struct usbd_msg *msg)
{
    if (msg->type == USBD_MSG_VBUS_READY) {
        (void)usbd_enable(ctx);
    } else if (msg->type == USBD_MSG_VBUS_REMOVED) {
        (void)usbd_disable(ctx);
    }
}

int receiver_usb_init(void)
{
    int rc;
    usbd_device_set_code_triple(&receiver_usb, USBD_SPEED_FS, USB_BCC_MISCELLANEOUS, 2, 1);
    rc = usbd_msg_register_cb(&receiver_usb, usb_event);
    if (rc) return rc;
    rc = bring_up(false);
    if (!rc) {
        atomic_set(&started, 1);
        k_work_submit(&class_work);
    }
    return rc;
}
```
